CM_ "IMPORT _toyota_2017.dbc";
CM_ "IMPORT _toyota_adas_standard.dbc";

CM_ "Override: 7-byte PCM_CRUISE for 2017 Lexus RC F (shifted signal positions)";

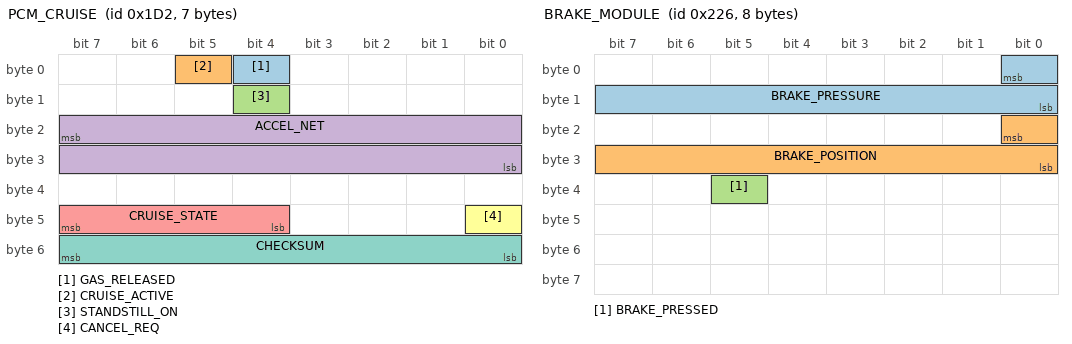
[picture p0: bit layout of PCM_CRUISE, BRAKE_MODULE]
BO_ 466 PCM_CRUISE: 7 XXX
 SG_ GAS_RELEASED : 4|1@0+ (1,0) [0|1] "" XXX
 SG_ CRUISE_ACTIVE : 5|1@0+ (1,0) [0|1] "" XXX
 SG_ STANDSTILL_ON : 12|1@0+ (1,0) [0|1] "" XXX
 SG_ ACCEL_NET : 23|16@0- (0.001,0) [-20|20] "m/s^2" XXX
 SG_ CRUISE_STATE : 47|4@0+ (1,0) [0|15] "" XXX
 SG_ CANCEL_REQ : 40|1@1+ (1,0) [0|1] "" XXX
 SG_ CHECKSUM : 55|8@0+ (1,0) [0|255] "" XXX

BO_ 550 BRAKE_MODULE: 8 XXX
 SG_ BRAKE_PRESSURE : 0|9@0+ (1,0) [0|511] "" XXX
 SG_ BRAKE_POSITION : 16|9@0+ (1,0) [0|511] "" XXX
 SG_ BRAKE_PRESSED : 37|1@0+ (1,0) [0|1] "" XXX

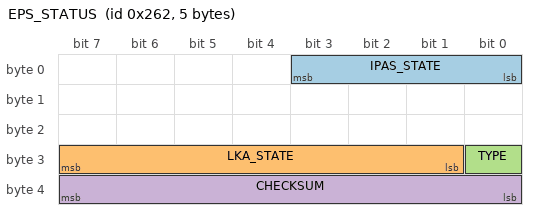
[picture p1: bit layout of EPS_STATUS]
BO_ 610 EPS_STATUS: 5 EPS
 SG_ IPAS_STATE : 3|4@0+ (1,0) [0|15] "" XXX
 SG_ LKA_STATE : 31|7@0+ (1,0) [0|127] "" XXX
 SG_ TYPE : 24|1@0+ (1,0) [0|1] "" XXX
 SG_ CHECKSUM : 39|8@0+ (1,0) [0|255] "" XXX

CM_ SG_ 466 ACCEL_NET "net negative acceleration (braking) applied by the system if on flat ground";
CM_ SG_ 466 CRUISE_STATE "Active state is 8, if standstill is requested will switch to state 11(3 sec timer), after timer is elapsed will switch into state 7(standstill)";
CM_ SG_ 550 BRAKE_PRESSURE "seems prop to pedal force";
CM_ SG_ 550 BRAKE_POSITION "seems proportional to pedal displacement, unclear the max value of 0x1c8";
CM_ SG_ 610 TYPE "seems 1 on Corolla, 0 on all others";

VAL_ 466 CRUISE_STATE 11 "timer_3sec" 10 "adaptive click down" 9 "adaptive click up" 8 "adaptive engaged" 7 "standstill" 6 "non-adaptive click up" 5 "non-adaptive click down" 4 "non-adaptive hold down" 3 "non-adaptive hold up" 2 "non-adaptive being engaged" 1 "non-adaptive engaged" 0 "off";
VAL_ 610 IPAS_STATE 5 "override" 3 "enabled" 1 "disabled";
VAL_ 610 LKA_STATE 25 "temporary_fault" 9 "temporary_fault2" 5 "active" 1 "standby";
